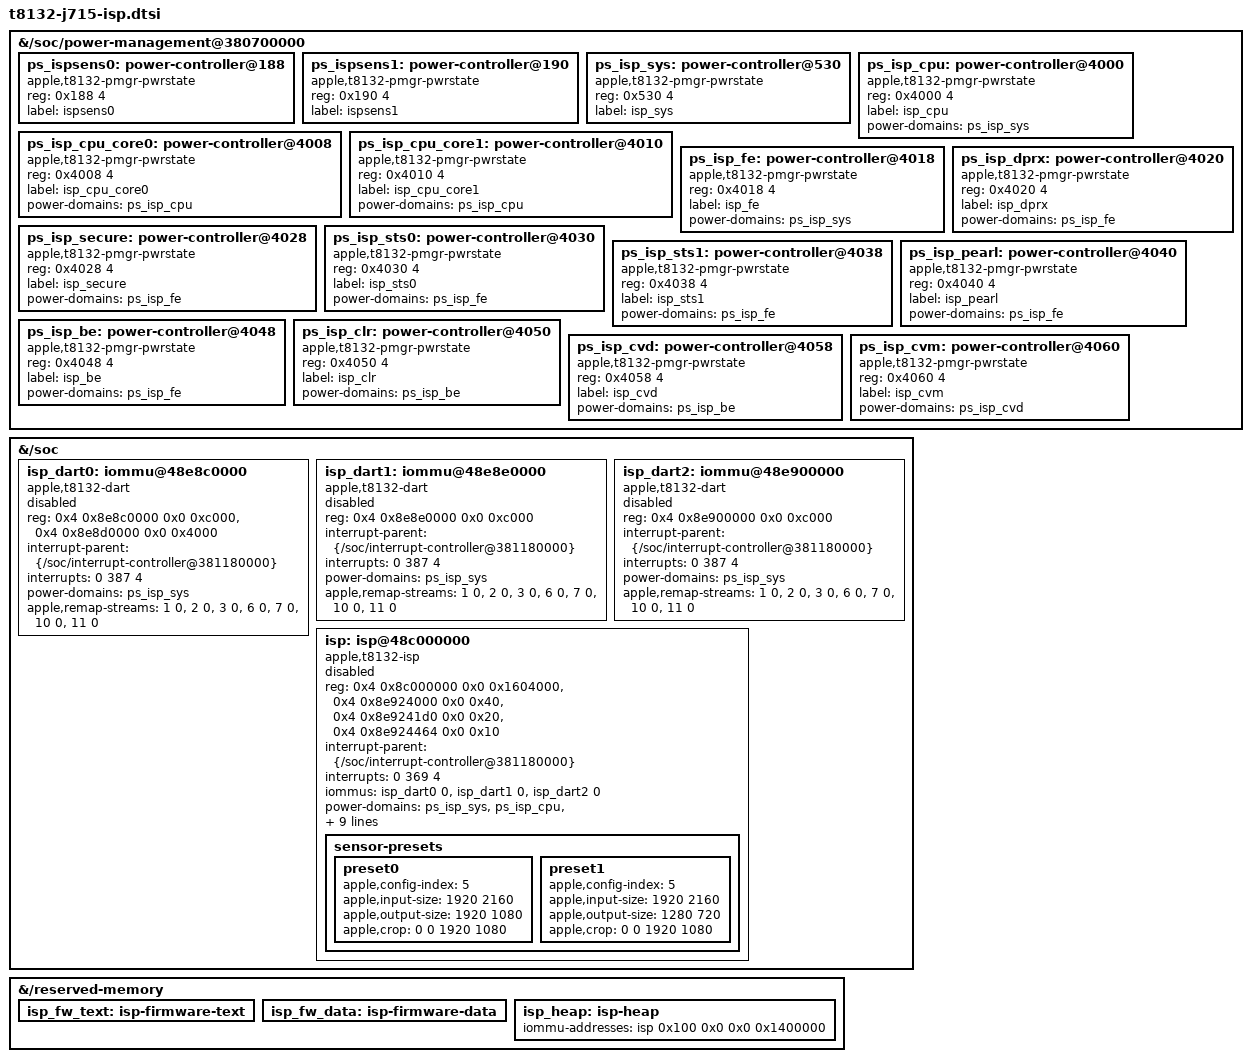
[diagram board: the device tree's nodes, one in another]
// SPDX-License-Identifier: GPL-2.0+ OR MIT
/*
 * J715 camera description, appended to the decompiled live J715 tree
 * (c16a7529...) for a local test. It only adds nodes; everything is disabled.
 * The boot loader's J713/J715 ISP handoff (variant D stage2) fills the empty
 * firmware placeholders from this boot's ADT and enables the ISP and DARTs.
 * Without that handoff the camera stays disabled.
 *
 * Values follow aurora-silicon/linux (t8132.dtsi, t8132-pmgr.dtsi,
 * t8132-isp.dtsi; GPL-2.0+ OR MIT), including the J713's two presets.
 * No physical address is written here.
 */

&{/soc/power-management@380700000} {
	ps_ispsens0: power-controller@188 {
		compatible = "apple,t8132-pmgr-pwrstate", "apple,t8103-pmgr-pwrstate";
		reg = <0x188 4>;
		#power-domain-cells = <0>;
		#reset-cells = <0>;
		label = "ispsens0";
	};

	ps_ispsens1: power-controller@190 {
		compatible = "apple,t8132-pmgr-pwrstate", "apple,t8103-pmgr-pwrstate";
		reg = <0x190 4>;
		#power-domain-cells = <0>;
		#reset-cells = <0>;
		label = "ispsens1";
	};

	ps_isp_sys: power-controller@530 {
		compatible = "apple,t8132-pmgr-pwrstate", "apple,t8103-pmgr-pwrstate";
		reg = <0x530 4>;
		#power-domain-cells = <0>;
		#reset-cells = <0>;
		label = "isp_sys";
	};

	ps_isp_cpu: power-controller@4000 {
		compatible = "apple,t8132-pmgr-pwrstate", "apple,t8103-pmgr-pwrstate";
		reg = <0x4000 4>;
		#power-domain-cells = <0>;
		#reset-cells = <0>;
		label = "isp_cpu";
		power-domains = <&ps_isp_sys>;
	};

	ps_isp_cpu_core0: power-controller@4008 {
		compatible = "apple,t8132-pmgr-pwrstate", "apple,t8103-pmgr-pwrstate";
		reg = <0x4008 4>;
		#power-domain-cells = <0>;
		#reset-cells = <0>;
		label = "isp_cpu_core0";
		power-domains = <&ps_isp_cpu>;
	};

	ps_isp_cpu_core1: power-controller@4010 {
		compatible = "apple,t8132-pmgr-pwrstate", "apple,t8103-pmgr-pwrstate";
		reg = <0x4010 4>;
		#power-domain-cells = <0>;
		#reset-cells = <0>;
		label = "isp_cpu_core1";
		power-domains = <&ps_isp_cpu>;
	};

	ps_isp_fe: power-controller@4018 {
		compatible = "apple,t8132-pmgr-pwrstate", "apple,t8103-pmgr-pwrstate";
		reg = <0x4018 4>;
		#power-domain-cells = <0>;
		#reset-cells = <0>;
		label = "isp_fe";
		power-domains = <&ps_isp_sys>;
	};

	ps_isp_dprx: power-controller@4020 {
		compatible = "apple,t8132-pmgr-pwrstate", "apple,t8103-pmgr-pwrstate";
		reg = <0x4020 4>;
		#power-domain-cells = <0>;
		#reset-cells = <0>;
		label = "isp_dprx";
		power-domains = <&ps_isp_fe>;
	};

	ps_isp_secure: power-controller@4028 {
		compatible = "apple,t8132-pmgr-pwrstate", "apple,t8103-pmgr-pwrstate";
		reg = <0x4028 4>;
		#power-domain-cells = <0>;
		#reset-cells = <0>;
		label = "isp_secure";
		power-domains = <&ps_isp_fe>;
	};

	ps_isp_sts0: power-controller@4030 {
		compatible = "apple,t8132-pmgr-pwrstate", "apple,t8103-pmgr-pwrstate";
		reg = <0x4030 4>;
		#power-domain-cells = <0>;
		#reset-cells = <0>;
		label = "isp_sts0";
		power-domains = <&ps_isp_fe>;
	};

	ps_isp_sts1: power-controller@4038 {
		compatible = "apple,t8132-pmgr-pwrstate", "apple,t8103-pmgr-pwrstate";
		reg = <0x4038 4>;
		#power-domain-cells = <0>;
		#reset-cells = <0>;
		label = "isp_sts1";
		power-domains = <&ps_isp_fe>;
	};

	ps_isp_pearl: power-controller@4040 {
		compatible = "apple,t8132-pmgr-pwrstate", "apple,t8103-pmgr-pwrstate";
		reg = <0x4040 4>;
		#power-domain-cells = <0>;
		#reset-cells = <0>;
		label = "isp_pearl";
		power-domains = <&ps_isp_fe>;
	};

	ps_isp_be: power-controller@4048 {
		compatible = "apple,t8132-pmgr-pwrstate", "apple,t8103-pmgr-pwrstate";
		reg = <0x4048 4>;
		#power-domain-cells = <0>;
		#reset-cells = <0>;
		label = "isp_be";
		power-domains = <&ps_isp_fe>;
	};

	ps_isp_clr: power-controller@4050 {
		compatible = "apple,t8132-pmgr-pwrstate", "apple,t8103-pmgr-pwrstate";
		reg = <0x4050 4>;
		#power-domain-cells = <0>;
		#reset-cells = <0>;
		label = "isp_clr";
		power-domains = <&ps_isp_be>;
	};

	ps_isp_cvd: power-controller@4058 {
		compatible = "apple,t8132-pmgr-pwrstate", "apple,t8103-pmgr-pwrstate";
		reg = <0x4058 4>;
		#power-domain-cells = <0>;
		#reset-cells = <0>;
		label = "isp_cvd";
		power-domains = <&ps_isp_be>;
	};

	ps_isp_cvm: power-controller@4060 {
		compatible = "apple,t8132-pmgr-pwrstate", "apple,t8103-pmgr-pwrstate";
		reg = <0x4060 4>;
		#power-domain-cells = <0>;
		#reset-cells = <0>;
		label = "isp_cvm";
		power-domains = <&ps_isp_cvd>;
	};
};

&{/soc} {
	isp_dart0: iommu@48e8c0000 {
		compatible = "apple,t8132-dart", "apple,t8110-dart";
		reg = <0x4 0x8e8c0000 0x0 0xc000>, <0x4 0x8e8d0000 0x0 0x4000>;
		reg-names = "dart", "dapf";
		#iommu-cells = <1>;
		interrupt-parent = <&{/soc/interrupt-controller@381180000}>;
		interrupts = <0 387 4>;
		power-domains = <&ps_isp_sys>;
		apple,remap-streams = <1 0>, <2 0>, <3 0>, <6 0>, <7 0>, <10 0>, <11 0>;
		status = "disabled";
	};

	isp_dart1: iommu@48e8e0000 {
		compatible = "apple,t8132-dart", "apple,t8110-dart";
		reg = <0x4 0x8e8e0000 0x0 0xc000>;
		#iommu-cells = <1>;
		interrupt-parent = <&{/soc/interrupt-controller@381180000}>;
		interrupts = <0 387 4>;
		power-domains = <&ps_isp_sys>;
		apple,remap-streams = <1 0>, <2 0>, <3 0>, <6 0>, <7 0>, <10 0>, <11 0>;
		status = "disabled";
	};

	isp_dart2: iommu@48e900000 {
		compatible = "apple,t8132-dart", "apple,t8110-dart";
		reg = <0x4 0x8e900000 0x0 0xc000>;
		#iommu-cells = <1>;
		interrupt-parent = <&{/soc/interrupt-controller@381180000}>;
		interrupts = <0 387 4>;
		power-domains = <&ps_isp_sys>;
		apple,remap-streams = <1 0>, <2 0>, <3 0>, <6 0>, <7 0>, <10 0>, <11 0>;
		status = "disabled";
	};

	isp: isp@48c000000 {
		compatible = "apple,t8132-isp", "apple,isp";
		reg = <0x4 0x8c000000 0x0 0x1604000>,
		      <0x4 0x8e924000 0x0 0x40>,
		      <0x4 0x8e9241d0 0x0 0x20>,
		      <0x4 0x8e924464 0x0 0x10>;
		reg-names = "coproc", "mbox", "gpio", "mbox2";
		interrupt-parent = <&{/soc/interrupt-controller@381180000}>;
		interrupts = <0 369 4>;
		iommus = <&isp_dart0 0>, <&isp_dart1 0>, <&isp_dart2 0>;
		power-domains = <&ps_isp_sys>, <&ps_isp_cpu>,
				<&ps_isp_cpu_core0>, <&ps_isp_cpu_core1>,
				<&ps_isp_fe>, <&ps_isp_dprx>, <&ps_isp_secure>,
				<&ps_isp_sts0>, <&ps_isp_sts1>, <&ps_isp_pearl>,
				<&ps_isp_be>, <&ps_isp_clr>, <&ps_isp_cvd>,
				<&ps_isp_cvm>, <&ps_ispsens0>, <&ps_ispsens1>;
		apple,dart-vm-size = /bits/ 64 <0xdec00000>;
		memory-region = <&isp_fw_text>, <&isp_fw_data>, <&isp_heap>;
		memory-region-names = "text", "data", "heap";
		status = "disabled";

		/* The IMX958 presets streamed on the J713 (aurora-silicon/linux t8132-isp.dtsi). */
		sensor-presets {
			/* 1920x1080 */
			preset0 {
				apple,config-index = <5>;
				apple,input-size = <1920 2160>;
				apple,output-size = <1920 1080>;
				apple,crop = <0 0 1920 1080>;
			};
			/* 1280x720: the same window, scaled down */
			preset1 {
				apple,config-index = <5>;
				apple,input-size = <1920 2160>;
				apple,output-size = <1280 720>;
				apple,crop = <0 0 1920 1080>;
			};
		};
	};
};

&{/reserved-memory} {
	isp_fw_text: isp-firmware-text { };

	isp_fw_data: isp-firmware-data { };

	isp_heap: isp-heap {
		iommu-addresses = <&isp 0x100 0x0 0x0 0x1400000>;
	};
};
